# platform_designer_hps_system_hps_0_hps register map
Vendor: default_vendor.com; File version: 0.0
Registers are 32-bit, read-write, reset 0x0 unless marked. A register's access mark holds for its fields unless they carry their own. Offsets are from the block's base; [hi:lo] are bit positions.

## emac0 (part 3 of 5) — Registers in the EMAC module.
Base 0xFF700000
Same registers: emac1 0xFF702000
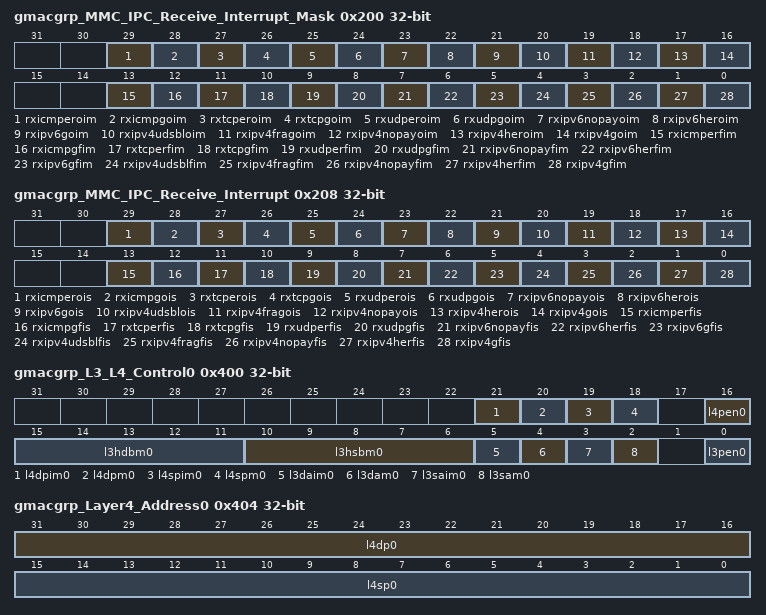
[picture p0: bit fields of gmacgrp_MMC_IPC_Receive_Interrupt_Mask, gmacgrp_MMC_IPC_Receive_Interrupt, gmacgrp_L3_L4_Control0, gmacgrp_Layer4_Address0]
0x200 gmacgrp_MMC_IPC_Receive_Interrupt_Mask — This register maintains the mask for the interrupt generated from the receive IPC statistic counters.
  [all] fields
    0=nomaskintr; 1=maskintr
  [29] rxicmperoim — Setting this bit masks the interrupt when the rxicmp_err_octets counter reaches half of the maximum value or the maximum value.
  [28] rxicmpgoim — Setting this bit masks the interrupt when the rxicmp_gd_octets counter reaches half of the maximum value or the maximum value.
  [27] rxtcperoim — Setting this bit masks the interrupt when the rxtcp_err_octets counter reaches half of the maximum value or the maximum value.
  [26] rxtcpgoim — Setting this bit masks the interrupt when the rxtcp_gd_octets counter reaches half of the maximum value or the maximum value.
  [25] rxudperoim — Setting this bit masks the interrupt when the rxudp_err_octets counter reaches half of the maximum value or the maximum value.
  [24] rxudpgoim — Setting this bit masks the interrupt when the rxudp_gd_octets counter reaches half of the maximum value or the maximum value.
  [23] rxipv6nopayoim — Setting this bit masks the interrupt when the rxipv6_nopay_octets counter reaches half of the maximum value or the maximum value.
  [22] rxipv6heroim — Setting this bit masks interrupt when the rxipv6_hdrerr_octets counter reaches half of the maximum value or the maximum value.
  [21] rxipv6goim — Setting this bit masks the interrupt when the rxipv6_gd_octets counter reaches half of the maximum value or the maximum value.
  [20] rxipv4udsbloim — Setting this bit masks the interrupt when the rxipv4_udsbl_octets counter reaches half of the maximum value or the maximum value.
  [19] rxipv4fragoim — Setting this bit masks the interrupt when the rxipv4_frag_octets counter reaches half of the maximum value or the maximum value.
  [18] rxipv4nopayoim — Setting this bit masks the interrupt when the rxipv4_nopay_octets counter reaches half of the maximum value or the maximum value.
  [17] rxipv4heroim — Setting this bit masks the interrupt when the rxipv4_hdrerr_octets counter reaches half of the maximum value or the maximum value.
  [16] rxipv4goim — Setting this bit masks the interrupt when the rxipv4_gd_octets counter reaches half of the maximum value or the maximum value.
  [13] rxicmperfim — Setting this bit masks the interrupt when the rxicmp_err_frms counter reaches half of the maximum value or the maximum value.
  [12] rxicmpgfim — Setting this bit masks the interrupt when the rxicmp_gd_frms counter reaches half of the maximum value or the maximum value.
  [11] rxtcperfim — Setting this bit masks the interrupt when the rxtcp_err_frms counter reaches half of the maximum value or the maximum value.
  [10] rxtcpgfim — Setting this bit masks the interrupt when the rxtcp_gd_frms counter reaches half of the maximum value or the maximum value.
  [9] rxudperfim — Setting this bit masks the interrupt when the rxudp_err_frms counter reaches half of the maximum value or the maximum value.
  [8] rxudpgfim — Setting this bit masks the interrupt when the rxudp_gd_frms counter reaches half of the maximum value or the maximum value.
  [7] rxipv6nopayfim — Setting this bit masks the interrupt when the rxipv6_nopay_frms counter reaches half of the maximum value or the maximum value.
  [6] rxipv6herfim — Setting this bit masks the interrupt when the rxipv6_hdrerr_frms counter reaches half of the maximum value or the maximum value.
  [5] rxipv6gfim — Setting this bit masks the interrupt when the rxipv6_gd_frms counter reaches half of the maximum value or the maximum value.
  [4] rxipv4udsblfim — Setting this bit masks the interrupt when the rxipv4_udsbl_frms counter reaches half of the maximum value or the maximum value.
  [3] rxipv4fragfim — Setting this bit masks the interrupt when the rxipv4_frag_frms counter reaches half of the maximum value or the maximum value.
  [2] rxipv4nopayfim — Setting this bit masks the interrupt when the rxipv4_nopay_frms counter reaches half of the maximum value or the maximum value.
  [1] rxipv4herfim — Setting this bit masks the interrupt when the rxipv4_hdrerr_frms counter reaches half of the maximum value or the maximum value.
  [0] rxipv4gfim — Setting this bit masks the interrupt when the rxipv4_gd_frms counter reaches half of the maximum value or the maximum value.
0x208 gmacgrp_MMC_IPC_Receive_Interrupt ro — This register maintains the interrupts generated when receive IPC statistic counters reach half their maximum values (0x8000_0000 for 32-bit counter and 0x8000 for 16-bit counter), and when they cross their maximum values (0xFFFF_FFFF for 32-bit counter and 0xFFFF for 16-bit counter). When Counter Stop Rollover is set, then interrupts are set but the counter remains at all-ones. The MMC Receive Checksum Offload Interrupt register is 32-bits wide. When the MMC IPC counter that caused the interrupt is read, its corresponding interrupt bit is cleared. The counter's least-significant byte lane (bits[7:0]) must be read to clear the interrupt bit.
  [all] fields
    0=nointerrupt; 1=interr
  [29] rxicmperois — This bit is set when the rxicmp_err_octets counter reaches half of the maximum value or the maximum value.
  [28] rxicmpgois — This bit is set when the rxicmp_gd_octets counter reaches half of the maximum value or the maximum value.
  [27] rxtcperois — This bit is set when the rxtcp_err_octets counter reaches half of the maximum value or the maximum value.
  [26] rxtcpgois — This bit is set when the rxtcp_gd_octets counter reaches half the maximum value or the maximum value.
  [25] rxudperois — This bit is set when the rxudp_err_octets counter reaches half the maximum value or the maximum value.
  [24] rxudpgois — This bit is set when the rxudp_gd_octets counter reaches half of the maximum value or the maximum value.
  [23] rxipv6nopayois — This bit is set when the rxipv6_nopay_octets counter reaches half of the maximum value or the maximum value.
  [22] rxipv6herois — This bit is set when the rxipv6_hdrerr_octets counter reaches half of the maximum value or the maximum value.
  [21] rxipv6gois — This bit is set when the rxipv6_gd_octets counter reaches half of the maximum value or the maximum value.
  [20] rxipv4udsblois — This bit is set when the rxipv4_udsbl_octets counter reaches half of the maximum value or the maximum value.
  [19] rxipv4fragois — This bit is set when the rxipv4_frag_octets counter reaches half of the maximum value or the maximum value.
  [18] rxipv4nopayois — This bit is set when the rxipv4_nopay_octets counter reaches half of the maximum value or the maximum value.
  [17] rxipv4herois — This bit is set when the rxipv4_hdrerr_octets counter reaches half of the maximum value or the maximum value.
  [16] rxipv4gois — This bit is set when the rxipv4_gd_octets counter reaches half of the maximum value or the maximum value.
  [13] rxicmperfis — This bit is set when the rxicmp_err_frms counter reaches half of the maximum value or the maximum value.
  [12] rxicmpgfis — This bit is set when the rxicmp_gd_frms counter reaches half of the maximum value or the maximum value.
  [11] rxtcperfis — This bit is set when the rxtcp_err_frms counter reaches half of the maximum value or the maximum value.
  [10] rxtcpgfis — This bit is set when the rxtcp_gd_frms counter reaches half of the maximum value or the maximum value.
  [9] rxudperfis — This bit is set when the rxudp_err_frms counter reaches half of the maximum value or the maximum value.
  [8] rxudpgfis — This bit is set when the rxudp_gd_frms counter reaches half of the maximum value or the maximum value.
  [7] rxipv6nopayfis — This bit is set when the rxipv6_nopay_frms counter reaches half of the maximum value or the maximum value.
  [6] rxipv6herfis — This bit is set when the rxipv6_hdrerr_frms counter reaches half of the maximum value or the maximum value.
  [5] rxipv6gfis — This bit is set when the rxipv6_gd_frms counter reaches half of the maximum value or the maximum value.
  [4] rxipv4udsblfis — This bit is set when the rxipv4_udsbl_frms counter reaches half of the maximum value or the maximum value.
  [3] rxipv4fragfis — This bit is set when the rxipv4_frag_frms counter reaches half of the maximum value or the maximum value.
  [2] rxipv4nopayfis — This bit is set when the rxipv4_nopay_frms counter reaches half of the maximum value or the maximum value.
  [1] rxipv4herfis — This bit is set when the rxipv4_hdrerr_frms counter reaches half of the maximum value or the maximum value.
  [0] rxipv4gfis — This bit is set when the rxipv4_gd_frms counter reaches half of the maximum value or the maximum value.
0x210 gmacgrp_rxipv4_gd_frms ro — Number of good IPv4 datagrams received with the TCP, UDP, or ICMP payload
  [31:0] cnt
0x214 gmacgrp_rxipv4_hdrerr_frms ro — Number of IPv4 datagrams received with header (checksum, length, or version mismatch) errors
  [31:0] cnt
0x218 gmacgrp_rxipv4_nopay_frms ro — Number of IPv4 datagram frames received that did not have a TCP, UDP, or ICMP payload processed by the Checksum engine
  [31:0] cnt
0x21C gmacgrp_rxipv4_frag_frms ro — Number of good IPv4 datagrams with fragmentation
  [31:0] cnt
0x220 gmacgrp_rxipv4_udsbl_frms ro — Number of good IPv4 datagrams received that had a UDP payload with checksum disabled
  [31:0] cnt
0x224 gmacgrp_rxipv6_gd_frms ro — Number of good IPv6 datagrams received with TCP, UDP, or ICMP payloads
  [31:0] cnt
0x228 gmacgrp_rxipv6_hdrerr_frms ro — Number of IPv6 datagrams received with header errors (length or version mismatch)
  [31:0] cnt
0x22C gmacgrp_rxipv6_nopay_frms ro — Number of IPv6 datagram frames received that did not have a TCP, UDP, or ICMP payload. This includes all IPv6 datagrams with fragmentation or security extension headers
  [31:0] cnt
0x230 gmacgrp_rxudp_gd_frms ro — Number of good IP datagrams with a good UDP payload. This counter is not updated when the counter is incremented
  [31:0] cnt
0x234 gmacgrp_rxudp_err_frms ro — Number of good IP datagrams whose UDP payload has a checksum error
  [31:0] cnt
0x238 gmacgrp_rxtcp_gd_frms ro — Number of good IP datagrams with a good TCP payload
  [31:0] cnt
0x23C gmacgrp_rxtcp_err_frms ro — Number of good IP datagrams whose TCP payload has a checksum error
  [31:0] cnt
0x240 gmacgrp_rxicmp_gd_frms ro — Number of good IP datagrams with a good ICMP payload
  [31:0] cnt
0x244 gmacgrp_rxicmp_err_frms ro — Number of good IP datagrams whose ICMP payload has a checksum error
  [31:0] cnt
0x250 gmacgrp_rxipv4_gd_octets ro — Number of bytes received in good IPv4 datagrams encapsulating TCP, UDP, or ICMP data
  [31:0] cnt
0x254 gmacgrp_rxipv4_hdrerr_octets ro — Number of bytes received in IPv4 datagrams with header errors (checksum, length, version mismatch). The value in the Length field of IPv4 header is used to update this counter
  [31:0] cnt
0x258 gmacgrp_rxipv4_nopay_octets ro — Number of bytes received in IPv4 datagrams that did not have a TCP, UDP, or ICMP payload. The value in the IPv4 headers Length field is used to update this counter
  [31:0] cnt
0x25C gmacgrp_rxipv4_frag_octets ro — Number of bytes received in fragmented IPv4 datagrams. The value in the IPv4 headers Length field is used to update this counter
  [31:0] cnt
0x260 gmacgrp_rxipv4_udsbl_octets ro — Number of bytes received in a UDP segment that had the UDP checksum disabled. This counter does not count IP Header bytes
  [31:0] cnt
0x264 gmacgrp_rxipv6_gd_octets ro — Number of bytes received in good IPv6 datagrams encapsulating TCP, UDP or ICMPv6 data
  [31:0] cnt
0x268 gmacgrp_rxipv6_hdrerr_octets ro — Number of bytes received in IPv6 datagrams with header errors (length, version mismatch). The value in the IPv6 headers Length field is used to update this counter
  [31:0] cnt
0x26C gmacgrp_rxipv6_nopay_octets ro — Number of bytes received in IPv6 datagrams that did not have a TCP, UDP, or ICMP payload. The value in the IPv6 headers Length field is used to update this counter
  [31:0] cnt
0x270 gmacgrp_rxudp_gd_octets ro — Number of bytes received in a good UDP segment. This counter does not count IP header bytes
  [31:0] cnt
0x274 gmacgrp_rxudp_err_octets ro — Number of bytes received in a UDP segment that had checksum errors
  [31:0] cnt
0x278 gmacgrp_rxtcp_gd_octets ro — Number of bytes received in a good TCP segment
  [31:0] cnt
0x27C gmacgrp_rxtcperroctets ro — Number of bytes received in a TCP segment with checksum errors
  [31:0] rxtcp_err_octets
0x280 gmacgrp_rxicmp_gd_octets ro — Number of bytes received in a good ICMP segment
  [31:0] cnt
0x284 gmacgrp_rxicmp_err_octets ro — Number of bytes received in an ICMP segment with checksum errors
  [31:0] cnt
0x400 gmacgrp_L3_L4_Control0 — This register controls the operations of the filter 0 of Layer 3 and Layer 4.
  [21] l4dpim0 — When set, this bit indicates that the Layer 4 Destination Port number field is enabled for inverse matching. When reset, this bit indicates that the Layer 4 Destination Port number field is enabled for perfect matching. This bit is valid and applicable only when Bit 20 (L4DPM0) is set high.
  [20] l4dpm0 — When set, this bit indicates that the Layer 4 Destination Port number field is enabled for matching. When reset, the MAC ignores the Layer 4 Destination Port number field for matching.
  [19] l4spim0 — When set, this bit indicates that the Layer 4 Source Port number field is enabled for inverse matching. When reset, this bit indicates that the Layer 4 Source Port number field is enabled for perfect matching. This bit is valid and applicable only when Bit 18 (L4SPM0) is set high.
  [18] l4spm0 — When set, this bit indicates that the Layer 4 Source Port number field is enabled for matching. When reset, the MAC ignores the Layer 4 Source Port number field for matching.
  [16] l4pen0 — When set, this bit indicates that the Source and Destination Port number fields for UDP frames are used for matching. When reset, this bit indicates that the Source and Destination Port number fields for TCP frames are used for matching. The Layer 4 matching is done only when either L4SPM0 or L4DPM0 bit is set high.
  [15:11] l3hdbm0 — IPv4 Frames: This field contains the number of higher bits of IP Destination Address that are matched in the IPv4 frames. The following list describes the values of this field: * 0: No bits are masked. * 1: LSb[0] is masked. * 2: Two LSbs [1:0] are masked. * ... * 31: All bits except MSb are masked. IPv6 Frames: Bits [12:11] of this field correspond to Bits [6:5] of L3HSBM0, which indicate the number of lower bits of IP Source or Destination Address that are masked in the IPv6 frames. The following list describes the concatenated values of the L3HDBM0[1:0] and L3HSBM0 bits: * 0: No bits are masked. * 1: LSb[0] is masked. * 2: Two LSbs [1:0] are masked. * ... * 127: All bits except MSb are masked. This field is valid and applicable only if L3DAM0 or L3SAM0 is set high.
  [10:6] l3hsbm0 — IPv4 Frames: This field contains the number of lower bits of IP Source Address that are masked for matching in the IPv4 frames. The following list describes the values of this field: * 0: No bits are masked. * 1: LSb[0] is masked. * 2: Two LSbs [1:0] are masked. * ... * 31: All bits except MSb are masked. IPv6 Frames: This field contains Bits [4:0] of the field that indicates the number of higher bits of IP Source or Destination Address matched in the IPv6 frames. This field is valid and applicable only if L3DAM0 or L3SAM0 is set high.
  [5] l3daim0 — When set, this bit indicates that the Layer 3 IP Destination Address field is enabled for inverse matching. When reset, this bit indicates that the Layer 3 IP Destination Address field is enabled for perfect matching. This bit is valid and applicable only when Bit 4 (L3DAM0) is set high.
  [4] l3dam0 — When set, this bit indicates that Layer 3 IP Destination Address field is enabled for matching. When reset, the MAC ignores the Layer 3 IP Destination Address field for matching. Note: When Bit 0 (L3PEN0) is set, you should set either this bit or Bit 2 (L3SAM0) because either IPv6 DA or SA can be checked for filtering.
  [3] l3saim0 — When set, this bit indicates that the Layer 3 IP Source Address field is enabled for inverse matching. When reset, this bit indicates that the Layer 3 IP Source Address field is enabled for perfect matching. This bit is valid and applicable only when Bit 2 (L3SAM0) is set high.
  [2] l3sam0 — When set, this bit indicates that the Layer 3 IP Source Address field is enabled for matching. When reset, the MAC ignores the Layer 3 IP Source Address field for matching. Note: When Bit 0 (L3PEN0) is set, you should set either this bit or Bit 4 (L3DAM0) because either IPv6 SA or DA can be checked for filtering.
  [0] l3pen0 — When set, this bit indicates that the Layer 3 IP Source or Destination Address matching is enabled for the IPv6 frames. When reset, this bit indicates that the Layer 3 IP Source or Destination Address matching is enabled for the IPv4 frames. The Layer 3 matching is done only when either L3SAM0 or L3DAM0 bit is set high.
0x404 gmacgrp_Layer4_Address0 — Because the Layer 3 and Layer 4 Address Registers are double-synchronized to the Rx clock domains, then the synchronization is triggered only when Bits[31:24] (in little-endian mode) or Bits[7:0] (in big-endian mode) of the Layer 3 and Layer 4 Address Registers are written. For proper synchronization updates, you should perform the consecutive writes to the same Layer 3 and Layer 4 Address Registers after at least four clock cycles delay of the destination clock.
  [31:16] l4dp0 — When Bit 16 (L4PEN0) is reset and Bit 20 (L4DPM0) is set in Register 256 (Layer 3 and Layer 4 Control Register 0), this field contains the value to be matched with the TCP Destination Port Number field in the IPv4 or IPv6 frames. When Bit 16 (L4PEN0) and Bit 20 (L4DPM0) are set in Register 256 (Layer 3 and Layer 4 Control Register 0), this field contains the value to be matched with the UDP Destination Port Number field in the IPv4 or IPv6 frames.
  [15:0] l4sp0 — Layer 4 Source Port Number Field When Bit 16 (L4PEN0) is reset and Bit 20 (L4DPM0) is set in Register 256 (Layer 3 and Layer 4 Control Register 0), this field contains the value to be matched with the TCP Source Port Number field in the IPv4 or IPv6 frames. When Bit 16 (L4PEN0) and Bit 20 (L4DPM0) are set in Register 256 (Layer 3 and Layer 4 Control Register 0), this field contains the value to be matched with the UDP Source Port Number field in the IPv4 or IPv6 frames.
0x410 gmacgrp_Layer3_Addr0_Reg0 — For IPv4 frames, the Layer 3 Address 0 Register 0 contains the 32-bit IP Source Address field. For IPv6 frames, it contains Bits[31:0] of the 128-bit IP Source Address or Destination Address field.
  [31:0] l3a00 — When Bit 0 (L3PEN0) and Bit 2 (L3SAM0) are set in Register 256 (Layer 3 and Layer 4 Control Register 0), this field contains the value to be matched with Bits[31:0] of the IP Source Address field in the IPv6 frames. When Bit 0 (L3PEN0) and Bit 4 (L3DAM0) are set in Register 256 (Layer 3 and Layer 4 Control Register 0), this field contains the value to be matched with Bits [31:0] of the IP Destination Address field in the IPv6 frames. When Bit 0 (L3PEN0) is reset and Bit 2 (L3SAM0) is set in Register 256 (Layer 3 and Layer 4 Control Register 0), this field contains the value to be matched with the IP Source Address field in the IPv4 frames.
0x414 gmacgrp_Layer3_Addr1_Reg0 — For IPv4 frames, the Layer 3 Address 1 Register 0 contains the 32-bit IP Destination Address field. For IPv6 frames, it contains Bits[63:32] of the 128-bit IP Source Address or Destination Address field.
  [31:0] l3a10 — When Bit 0 (L3PEN0) and Bit 2 (L3SAM0) are set in Register 256 (Layer 3 and Layer 4 Control Register 0), this field contains the value to be matched with Bits [63:32] of the IP Source Address field in the IPv6 frames. When Bit 0 (L3PEN0) and Bit 4 (L3DAM0) are set in Register 256 (Layer 3 and Layer 4 Control Register 0), this field contains the value to be matched with Bits [63:32] of the IP Destination Address field in the IPv6 frames. When Bit 0 (L3PEN0) is reset and Bit 4 (L3DAM0) is set in Register 256 (Layer 3 and Layer 4 Control Register 0), this field contains the value to be matched with the IP Destination Address field in the IPv4 frames.
0x418 gmacgrp_Layer3_Addr2_Reg0 — For IPv4 frames, the Layer 3 Address 2 Register 0 is reserved. For IPv6 frames, it contains Bits [95:64] of the 128-bit IP Source Address or Destination Address field.
  [31:0] l3a20 — When Bit 0 (L3PEN0) and Bit 2 (L3SAM0) are set in Register 256 (Layer 3 and Layer 4 Control Register 0), this field contains the value to be matched with Bits [95:64] of the IP Source Address field in the IPv6 frames. When Bit 0 (L3PEN0) and Bit 4 (L3DAM0) are set in Register 256 (Layer 3 and Layer 4 Control Register 0), this field contains value to be matched with Bits [95:64] of the IP Destination Address field in the IPv6 frames. When Bit 0 (L3PEN0) is reset in Register 256 (Layer 3 and Layer 4 Control Register 0), this register is not used.
0x41C gmacgrp_Layer3_Addr3_Reg0 — For IPv4 frames, the Layer 3 Address 3 Register 0 is reserved. For IPv6 frames, it contains Bits [127:96] of the 128-bit IP Source Address or Destination Address field.
  [31:0] l3a30 — When Bit 0 (L3PEN0) and Bit 2 (L3SAM0) are set in Register 256 (Layer 3 and Layer 4 Control Register 0), this field contains the value to be matched with Bits [127:96] of the IP Source Address field in the IPv6 frames. When Bit 0 (L3PEN0) and Bit 4 (L3DAM0) are set in Register 256 (Layer 3 and Layer 4 Control Register 0), this field contains the value to be matched with Bits [127:96] of the IP Destination Address field in the IPv6 frames. When Bit 0 (L3PEN0) is reset in Register 256 (Layer 3 and Layer 4 Control Register 0), this register is not used.
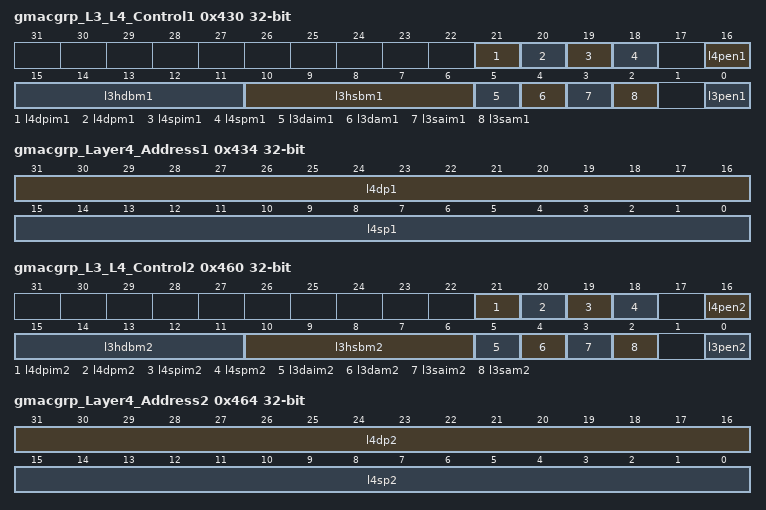
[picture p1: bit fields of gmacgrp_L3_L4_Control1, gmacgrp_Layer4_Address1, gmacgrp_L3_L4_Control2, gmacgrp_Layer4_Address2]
0x430 gmacgrp_L3_L4_Control1 — This register controls the operations of the filter 0 of Layer 3 and Layer 4.
  [21] l4dpim1 — When set, this bit indicates that the Layer 4 Destination Port number field is enabled for inverse matching. When reset, this bit indicates that the Layer 4 Destination Port number field is enabled for perfect matching. This bit is valid and applicable only when Bit 20 (L4DPM1) is set high.
  [20] l4dpm1 — When set, this bit indicates that the Layer 4 Destination Port number field is enabled for matching. When reset, the MAC ignores the Layer 4 Destination Port number field for matching.
  [19] l4spim1 — When set, this bit indicates that the Layer 4 Source Port number field is enabled for inverse matching. When reset, this bit indicates that the Layer 4 Source Port number field is enabled for perfect matching. This bit is valid and applicable only when Bit 18 (L4SPM1) is set high.
  [18] l4spm1 — When set, this bit indicates that the Layer 4 Source Port number field is enabled for matching. When reset, the MAC ignores the Layer 4 Source Port number field for matching.
  [16] l4pen1 — When set, this bit indicates that the Source and Destination Port number fields for UDP frames are used for matching. When reset, this bit indicates that the Source and Destination Port number fields for TCP frames are used for matching. The Layer 4 matching is done only when either L4SPM1 or L4DPM1 bit is set high.
  [15:11] l3hdbm1 — IPv4 Frames: This field contains the number of higher bits of IP Destination Address that are matched in the IPv4 frames. The following list describes the values of this field: * 0: No bits are masked. * 1: LSb[0] is masked. * 2: Two LSbs [1:0] are masked. * ... * 31: All bits except MSb are masked. IPv6 Frames: Bits [12:11] of this field correspond to Bits [6:5] of L3HSBM1, which indicate the number of lower bits of IP Source or Destination Address that are masked in the IPv6 frames. The following list describes the concatenated values of the L3HDBM1[1:0] and L3HSBM1 bits: * 0: No bits are masked. * 1: LSb[0] is masked. * 2: Two LSbs [1:0] are masked. * ... * 127: All bits except MSb are masked. This field is valid and applicable only if L3DAM1 or L3SAM1 is set high.
  [10:6] l3hsbm1 — IPv4 Frames: This field contains the number of lower bits of IP Source Address that are masked for matching in the IPv4 frames. The following list describes the values of this field: * 0: No bits are masked. * 1: LSb[0] is masked. * 2: Two LSbs [1:0] are masked. * ... * 31: All bits except MSb are masked. IPv6 Frames: This field contains Bits [4:0] of the field that indicates the number of higher bits of IP Source or Destination Address matched in the IPv6 frames. This field is valid and applicable only if L3DAM1 or L3SAM1 is set high.
  [5] l3daim1 — When set, this bit indicates that the Layer 3 IP Destination Address field is enabled for inverse matching. When reset, this bit indicates that the Layer 3 IP Destination Address field is enabled for perfect matching. This bit is valid and applicable only when Bit 4 (L3DAM1) is set high.
  [4] l3dam1 — When set, this bit indicates that Layer 3 IP Destination Address field is enabled for matching. When reset, the MAC ignores the Layer 3 IP Destination Address field for matching. Note: When Bit 1 (L3PEN1) is set, you should set either this bit or Bit 2 (L3SAM1) because either IPv6 DA or SA can be checked for filtering.
  [3] l3saim1 — When set, this bit indicates that the Layer 3 IP Source Address field is enabled for inverse matching. When reset, this bit indicates that the Layer 3 IP Source Address field is enabled for perfect matching. This bit is valid and applicable only when Bit 2 (L3SAM1) is set high.
  [2] l3sam1 — When set, this bit indicates that the Layer 3 IP Source Address field is enabled for matching. When reset, the MAC ignores the Layer 3 IP Source Address field for matching. Note: When Bit 0 (L3PEN1) is set, you should set either this bit or Bit 4 (L3DAM1) because either IPv6 SA or DA can be checked for filtering.
  [0] l3pen1 — When set, this bit indicates that the Layer 3 IP Source or Destination Address matching is enabled for the IPv6 frames. When reset, this bit indicates that the Layer 3 IP Source or Destination Address matching is enabled for the IPv4 frames. The Layer 3 matching is done only when either L3SAM1 or L3DAM1 bit is set high.
0x434 gmacgrp_Layer4_Address1 — Because the Layer 3 and Layer 4 Address Registers are double-synchronized to the Rx clock domains, then the synchronization is triggered only when Bits[31:24] (in little-endian mode) or Bits[7:0] (in big-endian mode) of the Layer 3 and Layer 4 Address Registers are written. For proper synchronization updates, you should perform the consecutive writes to the same Layer 3 and Layer 4 Address Registers after at least four clock cycles delay of the destination clock.
  [31:16] l4dp1 — When Bit 16 (L4PEN1) is reset and Bit 20 (L4DPM1) is set in Register 268 (Layer 3 and Layer 4 Control Register 0), this field contains the value to be matched with the TCP Destination Port Number field in the IPv4 or IPv6 frames. When Bit 16 (L4PEN1) and Bit 20 (L4DPM1) are set in Register 268 (Layer 3 and Layer 4 Control Register 1), this field contains the value to be matched with the UDP Destination Port Number field in the IPv4 or IPv6 frames.
  [15:0] l4sp1 — When Bit 16 (L4PEN1) is reset and Bit 20 (L4DPM1) is set in Register 268 (Layer 3 and Layer 4 Control Register 1), this field contains the value to be matched with the TCP Source Port Number field in the IPv4 or IPv6 frames. When Bit 16 (L4PEN1) and Bit 20 (L4DPM1) are set in Register 268 (Layer 3 and Layer 4 Control Register 1), this field contains the value to be matched with the UDP Source Port Number field in the IPv4 or IPv6 frames.
0x440 gmacgrp_Layer3_Addr0_Reg1 — For IPv4 frames, the Layer 3 Address 0 Register 1 contains the 32-bit IP Source Address field. For IPv6 frames, it contains Bits[31:0] of the 128-bit IP Source Address or Destination Address field.
  [31:0] l3a01 — When Bit 0 (L3PEN1) and Bit 2 (L3SAM1) are set in Register 268 (Layer 3 and Layer 4 Control Register 1), this field contains the value to be matched with Bits[31:0] of the IP Source Address field in the IPv6 frames. When Bit 0 (L3PEN1) and Bit 4 (L3DAM1) are set in Register 268 (Layer 3 and Layer 4 Control Register 1), this field contains the value to be matched with Bits [31:0] of the IP Destination Address field in the IPv6 frames. When Bit 0 (L3PEN1) is reset and Bit 2 (L3SAM1) is set in Register 268 (Layer 3 and Layer 4 Control Register 1), this field contains the value to be matched with the IP Source Address field in the IPv4 frames.
0x444 gmacgrp_Layer3_Addr1_Reg1 — For IPv4 frames, the Layer 3 Address 1 Register 1 contains the 32-bit IP Destination Address field. For IPv6 frames, it contains Bits[63:32] of the 128-bit IP Source Address or Destination Address field
  [31:0] l3a11 — When Bit 0 (L3PEN1) and Bit 2 (L3SAM1) are set in Register 268 (Layer 3 and Layer 4 Control Register 1), this field contains the value to be matched with Bits [63:32] of the IP Source Address field in the IPv6 frames. When Bit 0 (L3PEN1) and Bit 4 (L3DAM1) are set in Register 268 (Layer 3 and Layer 4 Control Register 1), this field contains the value to be matched with Bits [63:32] of the IP Destination Address field in the IPv6 frames. When Bit 0 (L3PEN1) is reset and Bit 4 (L3DAM1) is set in Register 268 (Layer 3 and Layer 4 Control Register 1), this field contains the value to be matched with the IP Destination Address field in the IPv4 frames.
0x448 gmacgrp_Layer3_Addr2_Reg1 — For IPv4 frames, the Layer 3 Address 2 Register 1 is reserved. For IPv6 frames, it contains Bits [95:64] of the 128-bit IP Source Address or Destination Address field.
  [31:0] l3a21 — When Bit 0 (L3PEN1) and Bit 2 (L3SAM1) are set in Register 268 (Layer 3 and Layer 4 Control Register 1), this field contains the value to be matched with Bits [95:64] of the IP Source Address field in the IPv6 frames. When Bit 0 (L3PEN1) and Bit 4 (L3DAM1) are set in Register 268 (Layer 3 and Layer 4 Control Register 1), this field contains value to be matched with Bits [95:64] of the IP Destination Address field in the IPv6 frames.
0x44C gmacgrp_Layer3_Addr3_Reg1 — For IPv4 frames, the Layer 3 Address 3 Register 1 is reserved. For IPv6 frames, it contains Bits [127:96] of the 128-bit IP Source Address or Destination Address field.
  [31:0] l3a31 — When Bit 1 (L3PEN1) and Bit 2 (L3SAM1) are set in Register 268 (Layer 3 and Layer 4 Control Register 1), this field contains the value to be matched with Bits [127:96] of the IP Source Address field in the IPv6 frames. When Bit 0 (L3PEN1) and Bit 4 (L3DAM1) are set in Register 268 (Layer 3 and Layer 4 Control Register 1), this field contains the value to be matched with Bits [127:96] of the IP Destination Address field in the IPv6 frames. When Bit 0 (L3PEN1) is reset in Register 268 (Layer 3 and Layer 4 Control Register 1), this register is not used.
0x460 gmacgrp_L3_L4_Control2 — This register controls the operations of the filter 2 of Layer 3 and Layer 4.
  [21] l4dpim2 — When set, this bit indicates that the Layer 4 Destination Port number field is enabled for inverse matching. When reset, this bit indicates that the Layer 4 Destination Port number field is enabled for perfect matching. This bit is valid and applicable only when Bit 20 (L4DPM0) is set high.
  [20] l4dpm2 — When set, this bit indicates that the Layer 4 Destination Port number field is enabled for matching. When reset, the MAC ignores the Layer 4 Destination Port number field for matching.
  [19] l4spim2 — When set, this bit indicates that the Layer 4 Source Port number field is enabled for inverse matching. When reset, this bit indicates that the Layer 4 Source Port number field is enabled for perfect matching. This bit is valid and applicable only when Bit 18 (L4SPM2) is set high.
  [18] l4spm2 — When set, this bit indicates that the Layer 4 Source Port number field is enabled for matching. When reset, the MAC ignores the Layer 4 Source Port number field for matching.
  [16] l4pen2 — When set, this bit indicates that the Source and Destination Port number fields for UDP frames are used for matching. When reset, this bit indicates that the Source and Destination Port number fields for TCP frames are used for matching. The Layer 4 matching is done only when either L4SPM2 or L4DPM2 bit is set high.
  [15:11] l3hdbm2 — IPv4 Frames: This field contains the number of higher bits of IP Destination Address that are matched in the IPv4 frames. The following list describes the values of this field: * 0: No bits are masked. * 1: LSb[0] is masked. * 2: Two LSbs [1:0] are masked. * ... * 31: All bits except MSb are masked. IPv6 Frames: Bits [12:11] of this field correspond to Bits [6:5] of L3HSBM2, which indicate the number of lower bits of IP Source or Destination Address that are masked in the IPv6 frames. The following list describes the concatenated values of the L3HDBM2[1:0] and L3HSBM2 bits: * 0: No bits are masked. * 1: LSb[0] is masked. * 2: Two LSbs [1:0] are masked. * ... * 127: All bits except MSb are masked. This field is valid and applicable only if L3DAM2 or L3SAM2 is set high.
  [10:6] l3hsbm2 — Layer 3 IP SA Higher Bits Match IPv4 Frames: This field contains the number of lower bits of IP Source Address that are masked for matching in the IPv4 frames. The following list describes the values of this field: * 0: No bits are masked. * 1: LSb[0] is masked. * 2: Two LSbs [1:0] are masked. * ... * 31: All bits except MSb are masked. IPv6 Frames: This field contains Bits [4:0] of the field that indicates the number of higher bits of IP Source or Destination Address matched in the IPv6 frames. This field is valid and applicable only if L3DAM2 or L3SAM2 is set high.
  [5] l3daim2 — When set, this bit indicates that the Layer 3 IP Destination Address field is enabled for inverse matching. When reset, this bit indicates that the Layer 3 IP Destination Address field is enabled for perfect matching. This bit is valid and applicable only when Bit 4 (L3DAM2) is set high.
  [4] l3dam2 — When set, this bit indicates that Layer 3 IP Destination Address field is enabled for matching. When reset, the MAC ignores the Layer 3 IP Destination Address field for matching. Note: When Bit 0 (L3PEN2) is set, you should set either this bit or Bit 2 (L3SAM2) because either IPv6 DA or SA can be checked for filtering.
  [3] l3saim2 — When set, this bit indicates that the Layer 3 IP Source Address field is enabled for inverse matching. When reset, this bit indicates that the Layer 3 IP Source Address field is enabled for perfect matching. This bit is valid and applicable only when Bit 2 (L3SAM2) is set high.
  [2] l3sam2 — When set, this bit indicates that the Layer 3 IP Source Address field is enabled for matching. When reset, the MAC ignores the Layer 3 IP Source Address field for matching. Note: When Bit 0 (L3PEN2) is set, you should set either this bit or Bit 4 (L3DAM2) because either IPv6 SA or DA can be checked for filtering.
  [0] l3pen2 — When set, this bit indicates that the Layer 3 IP Source or Destination Address matching is enabled for the IPv6 frames. When reset, this bit indicates that the Layer 3 IP Source or Destination Address matching is enabled for the IPv4 frames. The Layer 3 matching is done only when either L3SAM2 or L3DAM2 bit is set high.
0x464 gmacgrp_Layer4_Address2 — Because the Layer 3 and Layer 4 Address Registers are double-synchronized to the Rx clock domains, then the synchronization is triggered only when Bits[31:24] (in little-endian mode) or Bits[7:0] (in big-endian mode) of the Layer 3 and Layer 4 Address Registers are written. For proper synchronization updates, you should perform the consecutive writes to the same Layer 3 and Layer 4 Address Registers after at least four clock cycles delay of the destination clock.
  [31:16] l4dp2 — When Bit 16 (L4PEN2) is reset and Bit 20 (L4DPM2) is set in Register 280 (Layer 3 and Layer 4 Control Register 2), this field contains the value to be matched with the TCP Destination Port Number field in the IPv4 or IPv6 frames. When Bit 16 (L4PEN2) and Bit 20 (L4DPM2) are set in Register 280 (Layer 3 and Layer 4 Control Register 2), this field contains the value to be matched with the UDP Destination Port Number field in the IPv4 or IPv6 frames.
  [15:0] l4sp2 — When Bit 16 (L4PEN2) is reset and Bit 20 (L4DPM2) is set in Register 280 (Layer 3 and Layer 4 Control Register 2), this field contains the value to be matched with the TCP Source Port Number field in the IPv4 or IPv6 frames. When Bit 16 (L4PEN2) and Bit 20 (L4DPM2) are set in Register 280 (Layer 3 and Layer 4 Control Register 2), this field contains the value to be matched with the UDP Source Port Number field in the IPv4 or IPv6 frames.
0x470 gmacgrp_Layer3_Addr0_Reg2 — For IPv4 frames, the Layer 3 Address 0 Register 2 contains the 32-bit IP Source Address field. For IPv6 frames, it contains Bits [31:0] of the 128-bit IP Source Address or Destination Address field.
  [31:0] l3a02 — When Bit 0 (L3PEN2) and Bit 2 (L3SAM2) are set in Register 280 (Layer 3 and Layer 4 Control Register 2), this field contains the value to be matched with Bits [31:0] of the IP Source Address field in the IPv6 frames. When Bit 0 (L3PEN2) and Bit 4 (L3DAM2) are set in Register 280 (Layer 3 and Layer 4 Control Register 2), this field contains the value to be matched with Bits [31:0] of the IP Destination Address field in the IPv6 frames. When Bit 0 (L3PEN2) is reset and Bit 2 (L3SAM2) is set in Register 280 (Layer 3 and Layer 4 Control Register 2), this field contains the value to be matched with the IP Source Address field in the IPv4 frames.
